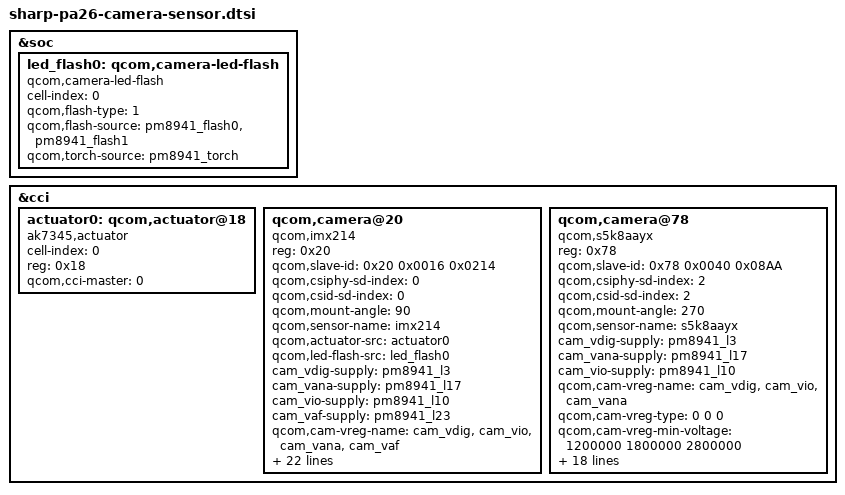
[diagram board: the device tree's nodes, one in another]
/*
 * Copyright (c) 2012-2014, The Linux Foundation. All rights reserved.
 *
 * This program is free software; you can redistribute it and/or modify
 * it under the terms of the GNU General Public License version 2 and
 * only version 2 as published by the Free Software Foundation.
 *
 * This program is distributed in the hope that it will be useful,
 * but WITHOUT ANY WARRANTY; without even the implied warranty of
 * MERCHANTABILITY or FITNESS FOR A PARTICULAR PURPOSE.  See the
 * GNU General Public License for more details.
 */

&soc {
	led_flash0: qcom,camera-led-flash {
		cell-index = <0>;
		compatible = "qcom,camera-led-flash";
		qcom,flash-type = <1>;
		qcom,flash-source = <&pm8941_flash0 &pm8941_flash1>;
		qcom,torch-source = <&pm8941_torch>;
	};
};

&cci {

	actuator0: qcom,actuator@18 {
		cell-index = <0>;
		reg = <0x18>;
		compatible = "ak7345,actuator";
		qcom,cci-master = <0>;
	};


    qcom,camera@20 {
		compatible = "qcom,imx214";
		reg = <0x20>;
		qcom,slave-id = <0x20 0x0016 0x0214>;
		qcom,csiphy-sd-index = <0>;
		qcom,csid-sd-index = <0>;
		qcom,mount-angle = <90>;
		qcom,sensor-name = "imx214";
		qcom,actuator-src = <&actuator0>;
		qcom,led-flash-src = <&led_flash0>;
		cam_vdig-supply = <&pm8941_l3>;
		cam_vana-supply = <&pm8941_l17>;
		cam_vio-supply = <&pm8941_l10>;
		cam_vaf-supply = <&pm8941_l23>;
		qcom,cam-vreg-name = "cam_vdig", "cam_vio", "cam_vana",
				     "cam_vaf";
		qcom,cam-vreg-type = <0 1 0 0>;
		qcom,cam-vreg-min-voltage = <1200000 1800000 2800000 3000000>;
		qcom,cam-vreg-max-voltage = <1200000 1800000 2800000 3000000>;
		qcom,cam-vreg-op-mode = <105000 0 80000 100000>;
		qcom,gpio-no-mux = <0>;
		gpios = <&msmgpio 15 0>,
			<&pm8941_gpios 13 0>;
		qcom,gpio-reset = <1>;
		qcom,gpio-req-tbl-num = <0 1>;
		qcom,gpio-req-tbl-flags = <1 0>;
		qcom,gpio-req-tbl-label = "CAMIF_MCLK",
					  "CAM_RESET1";
		qcom,gpio-set-tbl-num = <1 1>;
		qcom,gpio-set-tbl-flags = <0 2>;
		qcom,gpio-set-tbl-delay = <1000 30000>;
		qcom,csi-lane-assign = <0x4320>;
		qcom,csi-lane-mask = <0x1F>;
		qcom,sensor-position = <0>;
		qcom,sensor-mode = <0>;
	        qcom,sensor-type = <0>;
		qcom,cci-master = <0>;
		status = "ok";
	};
	qcom,camera@78 {
		compatible = "qcom,s5k8aayx";
		reg = <0x78>;
		qcom,slave-id = <0x78 0x0040 0x08AA>;
		qcom,csiphy-sd-index = <2>;
		qcom,csid-sd-index = <2>;
		qcom,mount-angle = <270>;
		qcom,sensor-name = "s5k8aayx";
		cam_vdig-supply = <&pm8941_l3>;
		cam_vana-supply = <&pm8941_l17>;
		cam_vio-supply = <&pm8941_l10>;
		qcom,cam-vreg-name = "cam_vdig", "cam_vio", "cam_vana";
		qcom,cam-vreg-type = <0 0 0>;
		qcom,cam-vreg-min-voltage =  <1200000 1800000 2800000>;
		qcom,cam-vreg-max-voltage = <1200000 1800000 2800000>;
		qcom,cam-vreg-op-mode = <105000 80000 80000>;
		qcom,gpio-no-mux = <0>;
		gpios = <&msmgpio 16 0>,
			<&pm8941_gpios 14 0>;
		qcom,gpio-reset = <1>;
		qcom,gpio-req-tbl-num = <0 1>;
		qcom,gpio-req-tbl-flags = <1 0>;
		qcom,gpio-req-tbl-label = "CAMIF_MCLK", "CAM_RESET1";
		qcom,gpio-set-tbl-num = <1 1>;
		qcom,gpio-set-tbl-flags = <0 2>;
		qcom,gpio-set-tbl-delay = <1000 4000>;
		qcom,csi-lane-assign = <0x4320>;
		qcom,csi-lane-mask = <0x3>;
		qcom,sensor-position = <1>;
		qcom,sensor-mode = <0>;
		qcom,cci-master = <1>;
		status = "ok";
	};
};
